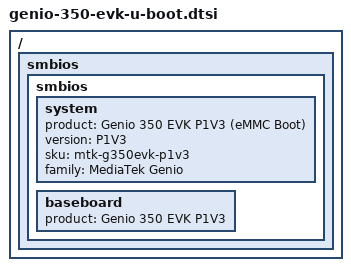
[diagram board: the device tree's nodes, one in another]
// SPDX-License-Identifier: GPL-2.0 OR MIT
/*
 * Copyright (C) 2025 MediaTek Inc.
 * Author: Pablo Sun <pablo.sun@mediatek.com>
 */

#include "smbios.dtsi"

/ {
	smbios {
		smbios {
			system {
				product = "Genio 350 EVK P1V3 (eMMC Boot)";
				version = "P1V3";
				sku = "mtk-g350evk-p1v3";
				family = "MediaTek Genio";
			};
			baseboard {
				product = "Genio 350 EVK P1V3";
			};
		};
	};
};
